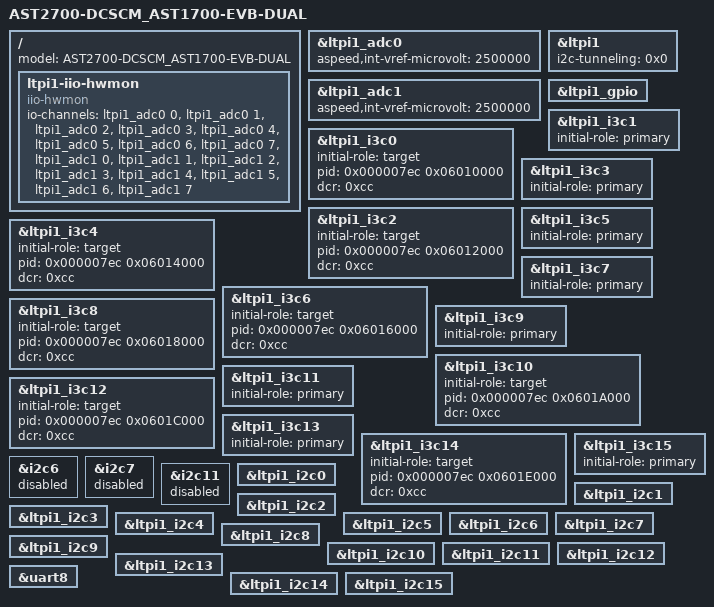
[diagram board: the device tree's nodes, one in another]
// SPDX-License-Identifier: GPL-2.0-or-later

/dts-v1/;

#include "ast2700-dcscm_ast1700-evb.dts"
#include "aspeed-ltpi1.dtsi"

/ {
	model = "AST2700-DCSCM_AST1700-EVB-DUAL";

	ltpi1-iio-hwmon {
		compatible = "iio-hwmon";
		io-channels = <&ltpi1_adc0 0>, <&ltpi1_adc0 1>, <&ltpi1_adc0 2>, <&ltpi1_adc0 3>,
				<&ltpi1_adc0 4>, <&ltpi1_adc0 5>, <&ltpi1_adc0 6>, <&ltpi1_adc0 7>,
				<&ltpi1_adc1 0>, <&ltpi1_adc1 1>, <&ltpi1_adc1 2>, <&ltpi1_adc1 3>,
				<&ltpi1_adc1 4>, <&ltpi1_adc1 5>, <&ltpi1_adc1 6>, <&ltpi1_adc1 7>;
	};
};

&ltpi1_adc0 {
	aspeed,int-vref-microvolt = <2500000>;
	status = "okay";
};

&ltpi1_adc1 {
	aspeed,int-vref-microvolt = <2500000>;
	status = "okay";
};

&ltpi1 {
	i2c-tunneling = <0x0>;
	status = "okay";
};

&ltpi1_gpio {
	status = "okay";
};

&ltpi1_i3c0 {
	initial-role = "target";
	pid = <0x000007ec 0x06010000>;
	dcr = /bits/ 8 <0xcc>;
	status = "okay";
};

&ltpi1_i3c1 {
	initial-role = "primary";
	status = "okay";
};

&ltpi1_i3c2 {
	initial-role = "target";
	pid = <0x000007ec 0x06012000>;
	dcr = /bits/ 8 <0xcc>;
	status = "okay";
};

&ltpi1_i3c3 {
	initial-role = "primary";
	status = "okay";
};

&ltpi1_i3c4 {
	initial-role = "target";
	pid = <0x000007ec 0x06014000>;
	dcr = /bits/ 8 <0xcc>;
	status = "okay";
};

&ltpi1_i3c5 {
	initial-role = "primary";
	status = "okay";
};

&ltpi1_i3c6 {
	initial-role = "target";
	pid = <0x000007ec 0x06016000>;
	dcr = /bits/ 8 <0xcc>;
	status = "okay";
};

&ltpi1_i3c7 {
	initial-role = "primary";
	status = "okay";
};

&ltpi1_i3c8 {
	initial-role = "target";
	pid = <0x000007ec 0x06018000>;
	dcr = /bits/ 8 <0xcc>;
	status = "okay";
};

&ltpi1_i3c9 {
	initial-role = "primary";
	status = "okay";
};

&ltpi1_i3c10 {
	initial-role = "target";
	pid = <0x000007ec 0x0601A000>;
	dcr = /bits/ 8 <0xcc>;
	status = "okay";
};

&ltpi1_i3c11 {
	initial-role = "primary";
	status = "okay";
};

&ltpi1_i3c12 {
	initial-role = "target";
	pid = <0x000007ec 0x0601C000>;
	dcr = /bits/ 8 <0xcc>;
	status = "okay";
};

&ltpi1_i3c13 {
	initial-role = "primary";
	status = "okay";
};

&ltpi1_i3c14 {
	initial-role = "target";
	pid = <0x000007ec 0x0601E000>;
	dcr = /bits/ 8 <0xcc>;
	status = "okay";
};

&ltpi1_i3c15 {
	initial-role = "primary";
	status = "okay";
};

&i2c6 {
	status = "disabled";
};

&i2c7 {
	status = "disabled";
};

// The following I2C buses require enabling according to the ast2700-dcscm.dts.
// i2c8 / i2c9 / i2c10

&i2c11 {
	status = "disabled";
};

&ltpi1_i2c0 {
	status = "okay";
};

&ltpi1_i2c1 {
	status = "okay";
};

&ltpi1_i2c2 {
	status = "okay";
};

&ltpi1_i2c3 {
	status = "okay";
};

&ltpi1_i2c4 {
	status = "okay";
};

&ltpi1_i2c5 {
	status = "okay";
};

&ltpi1_i2c6 {
	status = "okay";
};

&ltpi1_i2c7 {
	status = "okay";
};

&ltpi1_i2c8 {
	status = "okay";
};

&ltpi1_i2c9 {
	status = "okay";
};

&ltpi1_i2c10 {
	status = "okay";
};

&ltpi1_i2c11 {
	status = "okay";
};

&ltpi1_i2c12 {
	status = "okay";
};

&ltpi1_i2c13 {
	status = "okay";
};

&ltpi1_i2c14 {
	status = "okay";
};

&ltpi1_i2c15 {
	status = "okay";
};

&uart8 {
	/delete-property/ pinctrl-names;
	/delete-property/ pinctrl-0;
	status = "okay";
};
